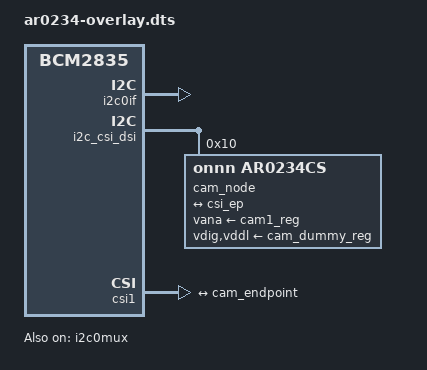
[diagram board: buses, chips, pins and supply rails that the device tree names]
// SPDX-License-Identifier: GPL-2.0-only
// Definitions for AR0234 camera module on VC I2C bus
/dts-v1/;
/plugin/;

#include <dt-bindings/gpio/gpio.h>

/{
	compatible = "brcm,bcm2835";

	fragment@0 {
		target = <&i2c0if>;
		__overlay__ {
			status = "okay";
		};
	};

	clk_frag: fragment@1 {
		target = <&cam1_clk>;
		__overlay__ {
			status = "okay";
			clock-frequency = <24000000>;
		};
	};

	fragment@2 {
		target = <&i2c0mux>;
		__overlay__ {
			status = "okay";
		};
	};

	i2c_frag: fragment@100 {
		target = <&i2c_csi_dsi>;
		__overlay__ {
			#address-cells = <1>;
			#size-cells = <0>;
			status = "okay";

			cam_node: ar0234@10 {
				compatible = "onnn,ar0234cs";
				reg = <0x10>;
				status = "okay";

				clocks = <&cam1_clk>;
				clock-names = "xclk";

				vana-supply = <&cam1_reg>;	/* 2.8v */
				vdig-supply = <&cam_dummy_reg>;	/* 1.8v */
				vddl-supply = <&cam_dummy_reg>;	/* 1.2v */

				port {
					cam_endpoint: endpoint {
						remote-endpoint = <&csi1_ep>;
						clock-lanes = <0>;
						data-lanes = <1 2>;
						clock-noncontinuous;
						link-frequencies =
							/bits/ 64 <450000000>;
					};
				};
			};
		};
	};

	csi_frag: fragment@101 {
		target = <&csi1>;
		csi: __overlay__ {
			status = "okay";
			brcm,media-controller;

			port {
				csi_ep: endpoint {
					remote-endpoint = <&cam_endpoint>;
					clock-lanes = <0>;
					data-lanes = <1 2>;
					clock-noncontinuous;
				};
			};
		};
	};

	__overrides__ {
		4lane = <0>, "-3+4-5+6";
		rotation = <&cam_node>,"rotation:0";
		orientation = <&cam_node>,"orientation:0";
		media-controller = <&csi>,"brcm,media-controller?";
		cam0 = <&i2c_frag>, "target:0=",<&i2c_csi_dsi0>,
		       <&csi_frag>, "target:0=",<&csi0>,
		       <&clk_frag>, "target:0=",<&cam0_clk>,
		       <&cam_node>, "clocks:0=",<&cam0_clk>,
		       <&cam_node>, "vana-supply:0=",<&cam0_reg>;
	};
};

&cam_node {
	status = "okay";
};

&cam_endpoint {
	remote-endpoint = <&csi_ep>;
};
